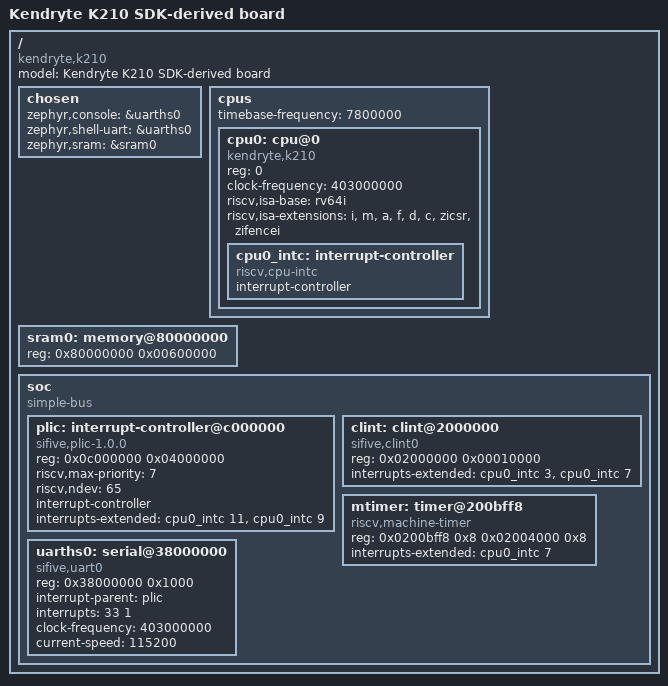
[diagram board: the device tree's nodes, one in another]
/dts-v1/;

/ {
	#address-cells = <1>;
	#size-cells = <1>;
	model = "Kendryte K210 SDK-derived board";
	compatible = "kendryte,k210";

	chosen {
		zephyr,console = &uarths0;
		zephyr,shell-uart = &uarths0;
		zephyr,sram = &sram0;
	};

	cpus {
		#address-cells = <1>;
		#size-cells = <0>;
		timebase-frequency = <7800000>;

		cpu0: cpu@0 {
			device_type = "cpu";
			compatible = "kendryte,k210", "riscv";
			reg = <0>;
			status = "okay";
			clock-frequency = <403000000>;
			riscv,isa-base = "rv64i";
			riscv,isa-extensions = "i", "m", "a", "f", "d", "c", "zicsr", "zifencei";

			cpu0_intc: interrupt-controller {
				compatible = "riscv,cpu-intc";
				#address-cells = <0>;
				#interrupt-cells = <1>;
				interrupt-controller;
			};
		};
	};

	sram0: memory@80000000 {
		device_type = "memory";
		reg = <0x80000000 0x00600000>;
	};

	soc {
		#address-cells = <1>;
		#size-cells = <1>;
		compatible = "simple-bus";
		ranges;

		plic: interrupt-controller@c000000 {
			compatible = "sifive,plic-1.0.0";
			reg = <0x0c000000 0x04000000>;
			riscv,max-priority = <7>;
			riscv,ndev = <65>;
			interrupt-controller;
			#address-cells = <0>;
			#interrupt-cells = <2>;
			interrupts-extended = <&cpu0_intc 11 &cpu0_intc 9>;
		};

		clint: clint@2000000 {
			compatible = "sifive,clint0";
			reg = <0x02000000 0x00010000>;
			interrupts-extended = <&cpu0_intc 3 &cpu0_intc 7>;
		};

		mtimer: timer@200bff8 {
			compatible = "riscv,machine-timer";
			reg = <0x0200bff8 0x8 0x02004000 0x8>;
			reg-names = "mtime", "mtimecmp";
			interrupts-extended = <&cpu0_intc 7>;
		};

		uarths0: serial@38000000 {
			compatible = "sifive,uart0";
			reg = <0x38000000 0x1000>;
			interrupt-parent = <&plic>;
			interrupts = <33 1>;
			clock-frequency = <403000000>;
			current-speed = <115200>;
			status = "okay";
		};
	};
};
